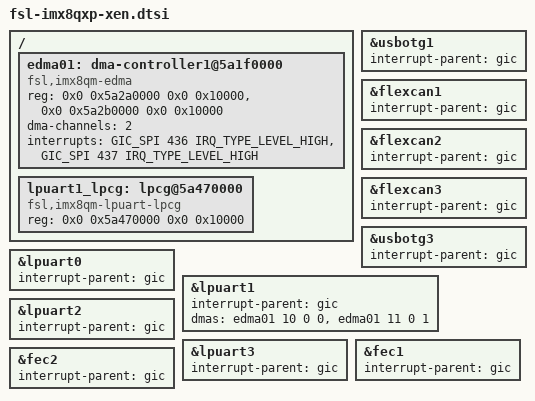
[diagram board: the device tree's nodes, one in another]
/*
 * Copyright 2018 NXP
 *
 * This program is free software; you can redistribute it and/or
 * modify it under the terms of the GNU General Public License
 * as published by the Free Software Foundation; either version 2
 * of the License, or (at your option) any later version.
 *
 * This program is distributed in the hope that it will be useful,
 * but WITHOUT ANY WARRANTY; without even the implied warranty of
 * MERCHANTABILITY or FITNESS FOR A PARTICULAR PURPOSE.  See the
 * GNU General Public License for more details.
 */

/ {
	/delete-node/ wu;

    edma01: dma-controller1@5a1f0000 {
        compatible = "fsl,imx8qm-edma";
        reg = <0x0 0x5a2a0000 0x0 0x10000>, /* channel10 UART1 rx */
              <0x0 0x5a2b0000 0x0 0x10000>; /* channel11 UART1 tx */
        #dma-cells = <3>;
        dma-channels = <2>;
        interrupts = <GIC_SPI 436 IRQ_TYPE_LEVEL_HIGH>,
                 <GIC_SPI 437 IRQ_TYPE_LEVEL_HIGH>;
        interrupt-names = "edma0-chan10-rx", "edma0-chan11-tx";
        status = "okay";
    };

	lpuart1_lpcg: lpcg@5a470000 {
		compatible = "fsl,imx8qm-lpuart-lpcg";
		reg = <0x0 0x5a470000 0x0 0x10000>;
	};
};

&usbotg1 {
	interrupt-parent = <&gic>;
};

&flexcan1 {
	interrupt-parent = <&gic>;
};

&flexcan2 {
	interrupt-parent = <&gic>;
};

&flexcan3 {
	interrupt-parent = <&gic>;
};

&usbotg3 {
	interrupt-parent = <&gic>;
};

&lpuart0 {
	interrupt-parent = <&gic>;
};

&lpuart1 {
	interrupt-parent = <&gic>;
	dmas = <&edma01 10 0 0>, <&edma01 11 0 1>;
};

&lpuart2 {
	interrupt-parent = <&gic>;
};

&lpuart3 {
	interrupt-parent = <&gic>;
};

&fec1 {
	interrupt-parent = <&gic>;
};

&fec2 {
	interrupt-parent = <&gic>;
};
